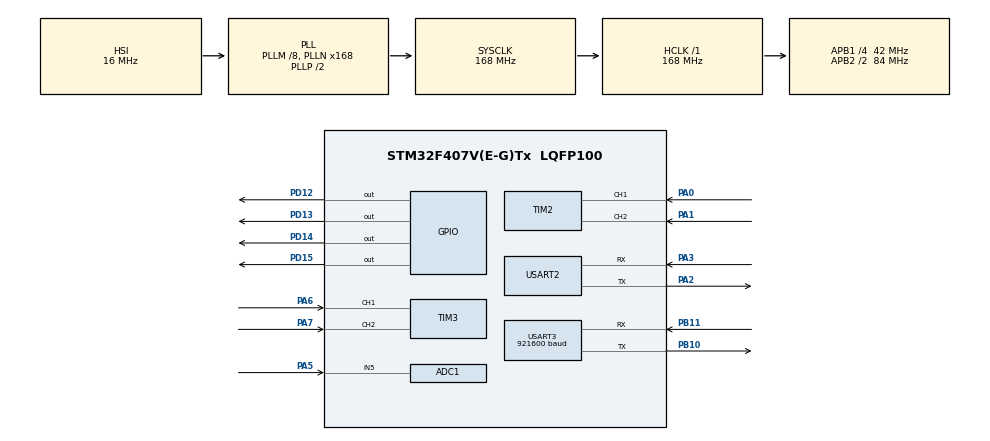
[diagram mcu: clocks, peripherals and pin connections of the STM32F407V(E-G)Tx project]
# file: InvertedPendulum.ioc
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ADC1.Channel-0\#ChannelRegularConversion=ADC_CHANNEL_5
ADC1.ContinuousConvMode=ENABLE
ADC1.DMAContinuousRequests=ENABLE
ADC1.NbrOfConversionFlag=1
ADC1.Rank-0\#ChannelRegularConversion=1
ADC1.SamplingTime-0\#ChannelRegularConversion=ADC_SAMPLETIME_15CYCLES
ADC1.master=1
Dma.ADC1.0.Direction=DMA_PERIPH_TO_MEMORY
Dma.ADC1.0.FIFOMode=DMA_FIFOMODE_DISABLE
Dma.ADC1.0.Instance=DMA2_Stream0
Dma.ADC1.0.MemDataAlignment=DMA_MDATAALIGN_HALFWORD
Dma.ADC1.0.MemInc=DMA_MINC_ENABLE
Dma.ADC1.0.Mode=DMA_CIRCULAR
Dma.ADC1.0.PeriphDataAlignment=DMA_PDATAALIGN_HALFWORD
Dma.ADC1.0.PeriphInc=DMA_PINC_DISABLE
Dma.ADC1.0.Priority=DMA_PRIORITY_LOW
Dma.Request0=ADC1
Mcu.Family=STM32F4
Mcu.Name=STM32F407V(E-G)Tx
Mcu.Package=LQFP100
NVIC.DMA2_Stream0_IRQn=true\:8\:0\:true\:false\:true\:false\:true\:true
NVIC.PriorityGroup=NVIC_PRIORITYGROUP_4
NVIC.TIM2_IRQn=true\:6\:0\:true\:false\:true\:true\:true\:true
NVIC.TIM3_IRQn=true\:7\:0\:true\:false\:true\:true\:true\:true
NVIC.TIM6_DAC_IRQn=true\:9\:0\:true\:false\:true\:true\:true\:true
NVIC.TIM7_IRQn=true\:10\:0\:true\:false\:true\:true\:true\:true
NVIC.USART2_IRQn=true\:11\:0\:true\:false\:true\:true\:true\:true
NVIC.USART3_IRQn=true\:12\:0\:true\:false\:true\:true\:true\:true
PA0-WKUP.Signal=S_TIM2_CH1_ETR
PA1.Signal=S_TIM2_CH2
PA13.Mode=Serial_Wire
PA13.Signal=SYS_JTMS-SWDIO
PA14.Mode=Serial_Wire
PA14.Signal=SYS_JTCK-SWCLK
PA2.Mode=Asynchronous
PA2.Signal=USART2_TX
PA3.Mode=Asynchronous
PA3.Signal=USART2_RX
PA5.Signal=ADCx_IN5
PA6.Signal=S_TIM3_CH1
PA7.Signal=S_TIM3_CH2
PB10.Mode=Asynchronous
PB10.Signal=USART3_TX
PB11.Mode=Asynchronous
PB11.Signal=USART3_RX
PD12.Signal=GPIO_Output
PD13.Signal=GPIO_Output
PD14.Signal=GPIO_Output
PD15.Signal=GPIO_Output
PH0-OSC_IN.Mode=HSE-External-Oscillator
PH0-OSC_IN.Signal=RCC_OSC_IN
PH1-OSC_OUT.Mode=HSE-External-Oscillator
PH1-OSC_OUT.Signal=RCC_OSC_OUT
ProjectManager.HeapSize=0x200
ProjectManager.StackSize=0x400
ProjectManager.TargetToolchain=Makefile
RCC.48MHZClocksFreq_Value=84000000
RCC.AHBFreq_Value=168000000
RCC.APB1CLKDivider=RCC_HCLK_DIV4
RCC.APB1Freq_Value=42000000
RCC.APB1TimFreq_Value=84000000
RCC.APB2CLKDivider=RCC_HCLK_DIV2
RCC.APB2Freq_Value=84000000
RCC.APB2TimFreq_Value=168000000
RCC.CortexFreq_Value=168000000
RCC.HCLKFreq_Value=168000000
RCC.HSE_VALUE=8000000
RCC.HSI_VALUE=16000000
RCC.LSE_VALUE=32768
RCC.PLLM=8
RCC.PLLN=168
RCC.SYSCLKFreq_VALUE=168000000
RCC.SYSCLKSource=RCC_SYSCLKSOURCE_PLLCLK
RCC.VCOOutputFreq_Value=336000000
SH.ADCx_IN5.0=ADC1_IN5,IN5
SH.S_TIM2_CH1_ETR.0=TIM2_CH1,Encoder_Interface
SH.S_TIM2_CH2.0=TIM2_CH2,Encoder_Interface
SH.S_TIM3_CH1.0=TIM3_CH1,Encoder_Interface
SH.S_TIM3_CH2.0=TIM3_CH2,Encoder_Interface
STMicroelectronics.X-CUBE-ALGOBUILD.1.4.0.LibraryCcDSPOoLibraryJjDSPOoLibrary=true
TIM2.AutoReloadPreload=TIM_AUTORELOAD_PRELOAD_ENABLE
TIM2.EncoderMode=TIM_ENCODERMODE_TI12
TIM2.IC1Polarity=TIM_ICPOLARITY_FALLING
TIM2.IC2Polarity=TIM_ICPOLARITY_FALLING
TIM3.EncoderMode=TIM_ENCODERMODE_TI12
TIM3.IC1Polarity=TIM_ICPOLARITY_FALLING
TIM3.IC2Polarity=TIM_ICPOLARITY_FALLING
TIM6.AutoReloadPreload=TIM_AUTORELOAD_PRELOAD_ENABLE
TIM6.Period=999
TIM6.Prescaler=839
TIM7.AutoReloadPreload=TIM_AUTORELOAD_PRELOAD_ENABLE
TIM7.Period=999
TIM7.Prescaler=83
USART2.VirtualMode=VM_ASYNC
USART3.BaudRate=921600
USART3.VirtualMode=VM_ASYNC
VP_STMicroelectronics.X-CUBE-ALGOBUILD_VS_DSPOoLibraryJjLibrary_1.4.0_1.4.0.Mode=DSPOoLibraryJjLibrary
VP_TIM6_VS_ClockSourceINT.Mode=Enable_Timer
VP_TIM7_VS_ClockSourceINT.Mode=Enable_Timer
board=custom

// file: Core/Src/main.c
/* USER CODE BEGIN Header */
/**
  ******************************************************************************
  * @file           : main.c
  * @brief          : Main program body
  ******************************************************************************
  * @attention
  *
  * Copyright (c) 2025 STMicroelectronics.
  * All rights reserved.
  *
  * This software is licensed under terms that can be found in the LICENSE file
  * in the root directory of this software component.
  * If no LICENSE file comes with this software, it is provided AS-IS.
  *
  ******************************************************************************
  */
/* USER CODE END Header */
#include "main.h"

ADC_HandleTypeDef hadc1;
DMA_HandleTypeDef hdma_adc1;

TIM_HandleTypeDef htim2;
TIM_HandleTypeDef htim3;
TIM_HandleTypeDef htim6;
TIM_HandleTypeDef htim7;

UART_HandleTypeDef huart2;
UART_HandleTypeDef huart3;

/* USER CODE BEGIN PV */
static struct Computer computer;
static struct Active * computer_AO = &computer.super;

static struct Estimator estimator;
static struct Active * estimator_AO = &estimator.super;

static struct Motor motor;
static struct Active * motor_AO = &motor.super;

/* USER CODE END PV */

void SystemClock_Config(void);
static void MX_GPIO_Init(void);
static void MX_DMA_Init(void);
static void MX_TIM2_Init(void);
static void MX_USART2_UART_Init(void);
static void MX_USART3_UART_Init(void);
static void MX_TIM6_Init(void);
static void MX_TIM7_Init(void);
static void MX_TIM3_Init(void);
static void MX_ADC1_Init(void);

int main(void)
{

  /* MCU Configuration--------------------------------------------------------*/

  /* Reset of all peripherals, Initializes the Flash interface and the Systick. */
  HAL_Init();

  /* Configure the system clock */
  SystemClock_Config();

  /* Initialize all configured peripherals */
  MX_GPIO_Init();
  MX_DMA_Init();
  MX_TIM2_Init();
  MX_USART2_UART_Init();
  MX_USART3_UART_Init();
  MX_TIM6_Init();
  MX_TIM7_Init();
  MX_TIM3_Init();
  MX_ADC1_Init();
  /* USER CODE BEGIN 2 */

  Computer.new(&computer);
  computer.super.start(computer_AO, 3, 20, 2000);

  Estimator.new(&estimator);
  estimator.super.start(estimator_AO, 2, 25, 3500);

  Motor.new(&motor);
  motor.super.start(motor_AO, 1, 20, 1500);

  vTaskStartScheduler();

  /* USER CODE END 2 */

  /* Infinite loop */
  while (1)
  {

  }
}

void SystemClock_Config(void)
{
  RCC_OscInitTypeDef RCC_OscInitStruct = {0};
  RCC_ClkInitTypeDef RCC_ClkInitStruct = {0};

  /** Configure the main internal regulator output voltage
  */
  __HAL_RCC_PWR_CLK_ENABLE();
  __HAL_PWR_VOLTAGESCALING_CONFIG(PWR_REGULATOR_VOLTAGE_SCALE1);

  /** Initializes the RCC Oscillators according to the specified parameters
  * in the RCC_OscInitTypeDef structure.
  */
  RCC_OscInitStruct.OscillatorType = RCC_OSCILLATORTYPE_HSI;
  RCC_OscInitStruct.HSIState = RCC_HSI_ON;
  RCC_OscInitStruct.HSICalibrationValue = RCC_HSICALIBRATION_DEFAULT;
  RCC_OscInitStruct.PLL.PLLState = RCC_PLL_ON;
  RCC_OscInitStruct.PLL.PLLSource = RCC_PLLSOURCE_HSI;
  RCC_OscInitStruct.PLL.PLLM = 8;
  RCC_OscInitStruct.PLL.PLLN = 168;
  RCC_OscInitStruct.PLL.PLLP = RCC_PLLP_DIV2;
  RCC_OscInitStruct.PLL.PLLQ = 4;
  if (HAL_RCC_OscConfig(&RCC_OscInitStruct) != HAL_OK)
  {
    Error_Handler();
  }

  /** Initializes the CPU, AHB and APB buses clocks
  */
  RCC_ClkInitStruct.ClockType = RCC_CLOCKTYPE_HCLK|RCC_CLOCKTYPE_SYSCLK
                              |RCC_CLOCKTYPE_PCLK1|RCC_CLOCKTYPE_PCLK2;
  RCC_ClkInitStruct.SYSCLKSource = RCC_SYSCLKSOURCE_PLLCLK;
  RCC_ClkInitStruct.AHBCLKDivider = RCC_SYSCLK_DIV1;
  RCC_ClkInitStruct.APB1CLKDivider = RCC_HCLK_DIV4;
  RCC_ClkInitStruct.APB2CLKDivider = RCC_HCLK_DIV2;

  if (HAL_RCC_ClockConfig(&RCC_ClkInitStruct, FLASH_LATENCY_5) != HAL_OK)
  {
    Error_Handler();
  }
}

static void MX_ADC1_Init(void)
{

  ADC_ChannelConfTypeDef sConfig = {0};

  /** Configure the global features of the ADC (Clock, Resolution, Data Alignment and number of conversion)
  */
  hadc1.Instance = ADC1;
  hadc1.Init.ClockPrescaler = ADC_CLOCK_SYNC_PCLK_DIV4;
  hadc1.Init.Resolution = ADC_RESOLUTION_12B;
  hadc1.Init.ScanConvMode = DISABLE;
  hadc1.Init.ContinuousConvMode = ENABLE;
  hadc1.Init.DiscontinuousConvMode = DISABLE;
  hadc1.Init.ExternalTrigConvEdge = ADC_EXTERNALTRIGCONVEDGE_NONE;
  hadc1.Init.ExternalTrigConv = ADC_SOFTWARE_START;
  hadc1.Init.DataAlign = ADC_DATAALIGN_RIGHT;
  hadc1.Init.NbrOfConversion = 1;
  hadc1.Init.DMAContinuousRequests = ENABLE;
  hadc1.Init.EOCSelection = ADC_EOC_SINGLE_CONV;
  if (HAL_ADC_Init(&hadc1) != HAL_OK)
  {
    Error_Handler();
  }

  /** Configure for the selected ADC regular channel its corresponding rank in the sequencer and its sample time.
  */
  sConfig.Channel = ADC_CHANNEL_5;
  sConfig.Rank = 1;
  sConfig.SamplingTime = ADC_SAMPLETIME_15CYCLES;
  if (HAL_ADC_ConfigChannel(&hadc1, &sConfig) != HAL_OK)
  {
    Error_Handler();
  }

}

static void MX_TIM2_Init(void)
{

  TIM_Encoder_InitTypeDef sConfig = {0};
  TIM_MasterConfigTypeDef sMasterConfig = {0};

  htim2.Instance = TIM2;
  htim2.Init.Prescaler = 0;
  htim2.Init.CounterMode = TIM_COUNTERMODE_UP;
  htim2.Init.Period = 4294967295;
  htim2.Init.ClockDivision = TIM_CLOCKDIVISION_DIV1;
  htim2.Init.AutoReloadPreload = TIM_AUTORELOAD_PRELOAD_ENABLE;
  sConfig.EncoderMode = TIM_ENCODERMODE_TI12;
  sConfig.IC1Polarity = TIM_ICPOLARITY_FALLING;
  sConfig.IC1Selection = TIM_ICSELECTION_DIRECTTI;
  sConfig.IC1Prescaler = TIM_ICPSC_DIV1;
  sConfig.IC1Filter = 0;
  sConfig.IC2Polarity = TIM_ICPOLARITY_FALLING;
  sConfig.IC2Selection = TIM_ICSELECTION_DIRECTTI;
  sConfig.IC2Prescaler = TIM_ICPSC_DIV1;
  sConfig.IC2Filter = 0;
  if (HAL_TIM_Encoder_Init(&htim2, &sConfig) != HAL_OK)
  {
    Error_Handler();
  }
  sMasterConfig.MasterOutputTrigger = TIM_TRGO_RESET;
  sMasterConfig.MasterSlaveMode = TIM_MASTERSLAVEMODE_DISABLE;
  if (HAL_TIMEx_MasterConfigSynchronization(&htim2, &sMasterConfig) != HAL_OK)
  {
    Error_Handler();
  }

}

static void MX_TIM3_Init(void)
{

  TIM_Encoder_InitTypeDef sConfig = {0};
  TIM_MasterConfigTypeDef sMasterConfig = {0};

  htim3.Instance = TIM3;
  htim3.Init.Prescaler = 0;
  htim3.Init.CounterMode = TIM_COUNTERMODE_UP;
  htim3.Init.Period = 65535;
  htim3.Init.ClockDivision = TIM_CLOCKDIVISION_DIV1;
  htim3.Init.AutoReloadPreload = TIM_AUTORELOAD_PRELOAD_DISABLE;
  sConfig.EncoderMode = TIM_ENCODERMODE_TI12;
  sConfig.IC1Polarity = TIM_ICPOLARITY_FALLING;
  sConfig.IC1Selection = TIM_ICSELECTION_DIRECTTI;
  sConfig.IC1Prescaler = TIM_ICPSC_DIV1;
  sConfig.IC1Filter = 0;
  sConfig.IC2Polarity = TIM_ICPOLARITY_FALLING;
  sConfig.IC2Selection = TIM_ICSELECTION_DIRECTTI;
  sConfig.IC2Prescaler = TIM_ICPSC_DIV1;
  sConfig.IC2Filter = 0;
  if (HAL_TIM_Encoder_Init(&htim3, &sConfig) != HAL_OK)
  {
    Error_Handler();
  }
  sMasterConfig.MasterOutputTrigger = TIM_TRGO_RESET;
  sMasterConfig.MasterSlaveMode = TIM_MASTERSLAVEMODE_DISABLE;
  if (HAL_TIMEx_MasterConfigSynchronization(&htim3, &sMasterConfig) != HAL_OK)
  {
    Error_Handler();
  }

}

static void MX_TIM6_Init(void)
{

  TIM_MasterConfigTypeDef sMasterConfig = {0};

  htim6.Instance = TIM6;
  htim6.Init.Prescaler = 839;
  htim6.Init.CounterMode = TIM_COUNTERMODE_UP;
  htim6.Init.Period = 999;
  htim6.Init.AutoReloadPreload = TIM_AUTORELOAD_PRELOAD_ENABLE;
  if (HAL_TIM_Base_Init(&htim6) != HAL_OK)
  {
    Error_Handler();
  }
  sMasterConfig.MasterOutputTrigger = TIM_TRGO_RESET;
  sMasterConfig.MasterSlaveMode = TIM_MASTERSLAVEMODE_DISABLE;
  if (HAL_TIMEx_MasterConfigSynchronization(&htim6, &sMasterConfig) != HAL_OK)
  {
    Error_Handler();
  }

}

static void MX_TIM7_Init(void)
{

  TIM_MasterConfigTypeDef sMasterConfig = {0};

  htim7.Instance = TIM7;
  htim7.Init.Prescaler = 83;
  htim7.Init.CounterMode = TIM_COUNTERMODE_UP;
  htim7.Init.Period = 999;
  htim7.Init.AutoReloadPreload = TIM_AUTORELOAD_PRELOAD_ENABLE;
  if (HAL_TIM_Base_Init(&htim7) != HAL_OK)
  {
    Error_Handler();
  }
  sMasterConfig.MasterOutputTrigger = TIM_TRGO_RESET;
  sMasterConfig.MasterSlaveMode = TIM_MASTERSLAVEMODE_DISABLE;
  if (HAL_TIMEx_MasterConfigSynchronization(&htim7, &sMasterConfig) != HAL_OK)
  {
    Error_Handler();
  }

}

static void MX_USART2_UART_Init(void)
{

  huart2.Instance = USART2;
  huart2.Init.BaudRate = 115200;
  huart2.Init.WordLength = UART_WORDLENGTH_8B;
  huart2.Init.StopBits = UART_STOPBITS_1;
  huart2.Init.Parity = UART_PARITY_NONE;
  huart2.Init.Mode = UART_MODE_TX_RX;
  huart2.Init.HwFlowCtl = UART_HWCONTROL_NONE;
  huart2.Init.OverSampling = UART_OVERSAMPLING_16;
  if (HAL_UART_Init(&huart2) != HAL_OK)
  {
    Error_Handler();
  }

}

static void MX_USART3_UART_Init(void)
{

  huart3.Instance = USART3;
  huart3.Init.BaudRate = 921600;
  huart3.Init.WordLength = UART_WORDLENGTH_8B;
  huart3.Init.StopBits = UART_STOPBITS_1;
  huart3.Init.Parity = UART_PARITY_NONE;
  huart3.Init.Mode = UART_MODE_TX_RX;
  huart3.Init.HwFlowCtl = UART_HWCONTROL_NONE;
  huart3.Init.OverSampling = UART_OVERSAMPLING_16;
  if (HAL_UART_Init(&huart3) != HAL_OK)
  {
    Error_Handler();
  }

}

static void MX_DMA_Init(void)
{

  /* DMA controller clock enable */
  __HAL_RCC_DMA2_CLK_ENABLE();

  /* DMA interrupt init */
  /* DMA2_Stream0_IRQn interrupt configuration */
  HAL_NVIC_SetPriority(DMA2_Stream0_IRQn, 8, 0);
  HAL_NVIC_EnableIRQ(DMA2_Stream0_IRQn);

}

static void MX_GPIO_Init(void)
{
  GPIO_InitTypeDef GPIO_InitStruct = {0};

  /* GPIO Ports Clock Enable */
  __HAL_RCC_GPIOH_CLK_ENABLE();
  __HAL_RCC_GPIOA_CLK_ENABLE();
  __HAL_RCC_GPIOB_CLK_ENABLE();
  __HAL_RCC_GPIOD_CLK_ENABLE();

  /*Configure GPIO pin Output Level */
  HAL_GPIO_WritePin(GPIOD, GPIO_PIN_12|GPIO_PIN_13|GPIO_PIN_14|GPIO_PIN_15, GPIO_PIN_RESET);

  /*Configure GPIO pins : PD12 PD13 PD14 PD15 */
  GPIO_InitStruct.Pin = GPIO_PIN_12|GPIO_PIN_13|GPIO_PIN_14|GPIO_PIN_15;
  GPIO_InitStruct.Mode = GPIO_MODE_OUTPUT_PP;
  GPIO_InitStruct.Pull = GPIO_NOPULL;
  GPIO_InitStruct.Speed = GPIO_SPEED_FREQ_LOW;
  HAL_GPIO_Init(GPIOD, &GPIO_InitStruct);

}

void Error_Handler(void)
{
  __disable_irq();
  while (1)
  {
  }
}
